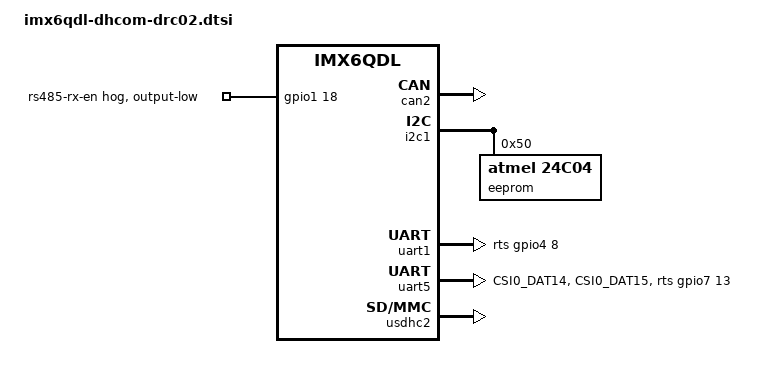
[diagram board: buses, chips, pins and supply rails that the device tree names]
/ {
	chosen {
		stdout-path = "serial0:115200n8";
	};
};
&can2 {
	status = "okay";
};
&gpio1 {
	rs485-rx-en-hog {
		gpio-hog;
		gpios = <18 0>;  
		line-name = "rs485-rx-en";
		output-low;
	};
};
&gpio3 {
	gpio-line-names =
		"", "", "", "", "", "", "", "",
		"", "", "", "", "", "", "", "",
		"", "", "", "", "", "", "", "",
		"", "", "", "DRC02-In1", "", "", "", "";
};
&gpio4 {
	gpio-line-names =
		"", "", "", "", "", "DHCOM-E", "DRC02-In2", "DHCOM-H",
		"DHCOM-I", "DRC02-HW0", "", "", "", "", "", "",
		"", "", "", "", "DRC02-Out1", "", "", "",
		"", "", "", "", "", "", "", "";
};
&gpio6 {
	gpio-line-names =
		"", "", "", "DRC02-Out2", "", "", "SOM-HW1", "",
		"", "", "", "", "", "", "DRC02-HW2", "DRC02-HW1",
		"", "", "", "", "", "", "", "",
		"", "", "", "", "", "", "", "";
};
&i2c1 {
	eeprom@50 {
		compatible = "atmel,24c04";
		reg = <0x50>;
		pagesize = <16>;
	};
};
&uart1 {
	/delete-property/ uart-has-rtscts;
	cts-gpios = <&gpio7 0 GPIO_ACTIVE_HIGH>;  
	pinctrl-0 = <&pinctrl_uart1 &pinctrl_dhcom_i &pinctrl_dhcom_m>;
	pinctrl-names = "default";
	rts-gpios = <&gpio4 8 GPIO_ACTIVE_HIGH>;  
};
&uart5 {
	/delete-property/ uart-has-rtscts;
	linux,rs485-enabled-at-boot-time;
	pinctrl-0 = <&pinctrl_uart5_core &pinctrl_dhcom_p &pinctrl_dhcom_q>;
	pinctrl-names = "default";
	rts-gpios = <&gpio7 13 GPIO_ACTIVE_HIGH>;  
};
&usbh1 {
	disable-over-current;
};
&usdhc2 {  
	status = "okay";
};
&usdhc3 {
	status = "disabled";
};
&iomuxc {
	pinctrl-0 = <
			&pinctrl_hog_base
			&pinctrl_dhcom_a &pinctrl_dhcom_b &pinctrl_dhcom_c
			&pinctrl_dhcom_d &pinctrl_dhcom_e &pinctrl_dhcom_f
			&pinctrl_dhcom_g &pinctrl_dhcom_h
			&pinctrl_dhcom_j &pinctrl_dhcom_k &pinctrl_dhcom_l
			&pinctrl_dhcom_n &pinctrl_dhcom_o
			&pinctrl_dhcom_r
			&pinctrl_dhcom_s &pinctrl_dhcom_t &pinctrl_dhcom_u
			&pinctrl_dhcom_v &pinctrl_dhcom_w &pinctrl_dhcom_int
		>;
	pinctrl-names = "default";
	pinctrl_uart5_core: uart5-core-grp {
		fsl,pins = <
			MX6QDL_PAD_CSI0_DAT14__UART5_TX_DATA	0x1b0b1
			MX6QDL_PAD_CSI0_DAT15__UART5_RX_DATA	0x1b0b1
		>;
	};
};
